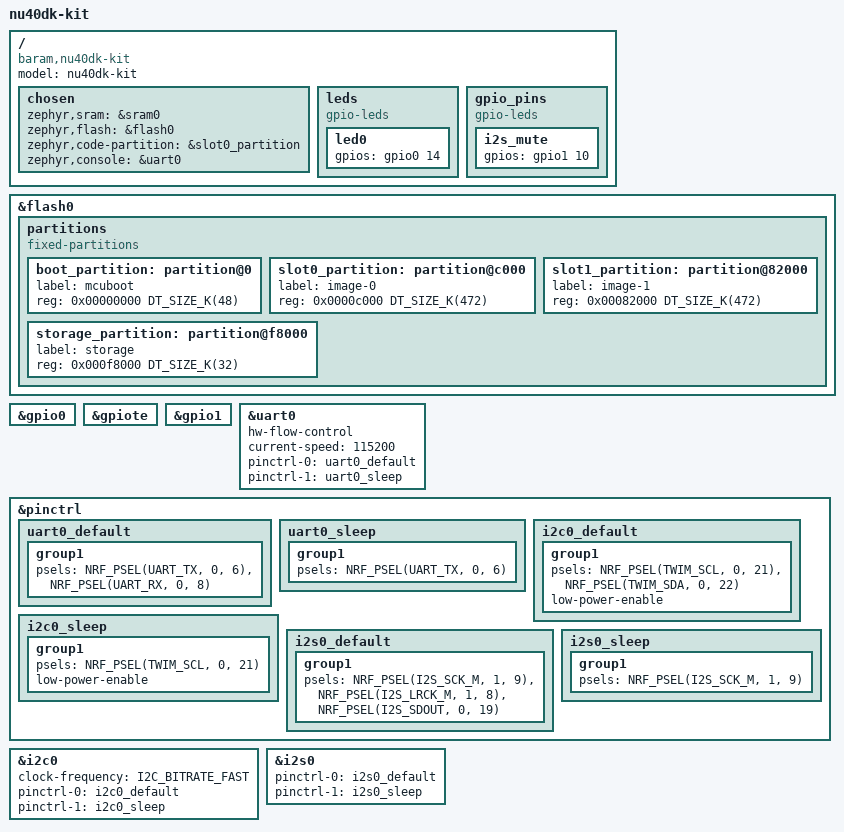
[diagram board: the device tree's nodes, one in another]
/dts-v1/;
#include <nordic/nrf52840_qiaa.dtsi>
#include "nu40dk_kit-pinctrl.dtsi"

/ {
	model = "nu40dk-kit";
	compatible = "baram,nu40dk-kit";

	chosen {
		zephyr,sram = &sram0;
		zephyr,flash = &flash0;
		zephyr,code-partition = &slot0_partition;
    zephyr,console = &uart0;
	};

  leds {
    compatible = "gpio-leds";
    led0: led0 {
      gpios = <&gpio0 14 0>;
    };
  };  

  gpio_pins {    		
		compatible = "gpio-leds";
		i2s_mute: i2s_mute {
			gpios = <&gpio1 10 GPIO_ACTIVE_HIGH>;
		}; 		
  };    
};

&flash0 {
	partitions {
		compatible = "fixed-partitions";
		#address-cells = <1>;
		#size-cells = <1>;

		boot_partition: partition@0 {
			label = "mcuboot";
			reg = <0x00000000 DT_SIZE_K(48)>;
		};

		slot0_partition: partition@c000 {
			label = "image-0";
			reg = <0x0000c000 DT_SIZE_K(472)>;
		};

		slot1_partition: partition@82000 {
			label = "image-1";
			reg = <0x00082000 DT_SIZE_K(472)>;
		};

		storage_partition: partition@f8000 {
			label = "storage";
			reg = <0x000f8000 DT_SIZE_K(32)>;
		};
	};
};

&gpio0 {
  status = "okay";
};

&gpiote {
  status = "okay";
};

&gpio1 {
  status = "okay";
};

&uart0 {
  status = "okay";
  hw-flow-control;
  current-speed = <115200>;
  pinctrl-0 = <&uart0_default>;
  pinctrl-1 = <&uart0_sleep>;
  pinctrl-names = "default", "sleep";
};

&pinctrl {
  uart0_default: uart0_default {
    group1 {
      psels = <NRF_PSEL(UART_TX, 0, 6)>, <NRF_PSEL(UART_RX, 0, 8)>;
    };
  };

  uart0_sleep: uart0_sleep {
    group1 {
      psels = <NRF_PSEL(UART_TX, 0, 6)>;
    };
  };

  i2c0_default: i2c0_default {
    group1 {
      psels = <NRF_PSEL(TWIM_SCL, 0, 21)>, <NRF_PSEL(TWIM_SDA, 0, 22)>;
      low-power-enable;
    };
  };

  i2c0_sleep: i2c0_sleep {
    group1 {
      psels = <NRF_PSEL(TWIM_SCL, 0, 21)>;
      low-power-enable;
    };
  };

  i2s0_default: i2s0_default {
    group1 {
      psels = <NRF_PSEL(I2S_SCK_M, 1, 9)>,
              <NRF_PSEL(I2S_LRCK_M, 1, 8)>,
              <NRF_PSEL(I2S_SDOUT, 0, 19)>;
    };
  };

  i2s0_sleep: i2s0_sleep {
    group1 {
      psels = <NRF_PSEL(I2S_SCK_M, 1, 9)>;
    };
  };
};

&i2c0 {
  status = "okay";
  clock-frequency = <I2C_BITRATE_FAST>;
  pinctrl-0 = <&i2c0_default>;
  pinctrl-1 = <&i2c0_sleep>;
  pinctrl-names = "default", "sleep";
};


&i2s0 {
  status = "okay";
  pinctrl-0 = <&i2s0_default>;
  pinctrl-1 = <&i2s0_sleep>;
  pinctrl-names = "default", "sleep";
};
